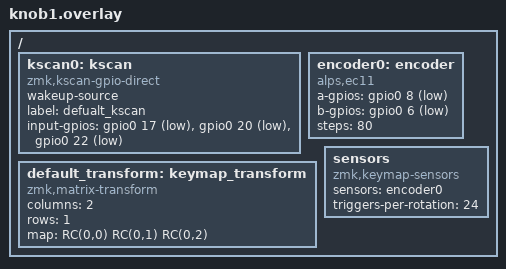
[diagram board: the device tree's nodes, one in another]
#include <dt-bindings/zmk/matrix_transform.h>
#include "knob1-layouts.dtsi"   

/ {
       /*chosen {
        zmk,physical-layout = &physical_layout0;
        // Other chosen items
    };*/

    kscan0: kscan {
        compatible = "zmk,kscan-gpio-direct";
        wakeup-source;
        label = "defualt_kscan";
        input-gpios =
            <&gpio0 17 (GPIO_ACTIVE_LOW | GPIO_PULL_UP)>,
            <&gpio0 20 (GPIO_ACTIVE_LOW | GPIO_PULL_UP)>,
            <&gpio0 22 (GPIO_ACTIVE_LOW | GPIO_PULL_UP)>;
    };

    encoder0: encoder{
        compatible = "alps,ec11";
        a-gpios = <&gpio0 8 (GPIO_ACTIVE_LOW | GPIO_PULL_UP)>;
        b-gpios = <&gpio0 6 (GPIO_ACTIVE_LOW | GPIO_PULL_UP)>;
        steps = <80>;
        status = "okay";
    };

    default_transform: keymap_transform {
        compatible = "zmk,matrix-transform";
        columns = <2>;
        rows = <1>;
        map = <
        //  Key 1
            RC(0,0)
        //  Key 2
            RC(0,1)
        // unlock studio
            RC(0,2)
        >;

    };

    sensors: sensors {
        compatible = "zmk,keymap-sensors";
        sensors = <&encoder0>;
        triggers-per-rotation = <24>;
    };
};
